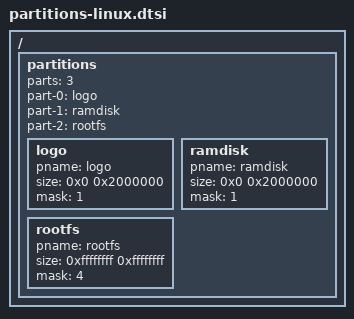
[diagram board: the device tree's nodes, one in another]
/*
 * arch/arm64/boot/dts/partitions.dtsi
 * Partitions for Linux Distro(i.e. Ubuntu)
 *
 * Copyright (C) 2017 Khadsa.com All rights reserved.
 *
 * This program is free software; you can redistribute it and/or modify
 * it under the terms of the GNU General Public License as published by
 * the Free Software Foundation; either version 2 of the License, or
 * (at your option) any later version.
 *
 * This program is distributed in the hope that it will be useful, but WITHOUT
 * ANY WARRANTY; without even the implied warranty of MERCHANTABILITY or
 * FITNESS FOR A PARTICULAR PURPOSE.  See the GNU General Public License for
 * more details.
 *
*/

/ {
	partitions: partitions{
        parts = <3>;
		part-0 = <&logo>;
		part-1 = <&ramdisk>;
		part-2 = <&rootfs>;

		logo:logo{
			pname = "logo";
			size = <0x0 0x2000000>;
			mask = <1>;
		};
		ramdisk:ramdisk
		{
			pname = "ramdisk";
			size = <0x0 0x2000000>;
			mask = <1>;
		};
		rootfs:rootfs
		{
			pname = "rootfs";
			size = <0xffffffff 0xffffffff>;
			mask = <4>;
		};
	};
};
